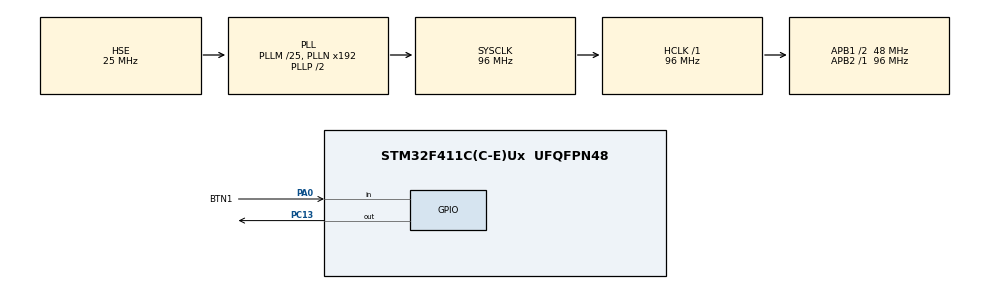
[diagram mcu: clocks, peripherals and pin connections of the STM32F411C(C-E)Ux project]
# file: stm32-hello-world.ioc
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FREERTOS.Queues01=buttonQueue,10,uint8_t,0,Dynamic,NULL,NULL
FREERTOS.Tasks01=defaultTask,24,128,StartDefaultTask,Default,NULL,Dynamic,NULL,NULL;buttonTask,40,128,StartButtonTask,Default,NULL,Dynamic,NULL,NULL
Mcu.Family=STM32F4
Mcu.Name=STM32F411C(C-E)Ux
Mcu.Package=UFQFPN48
NVIC.PriorityGroup=NVIC_PRIORITYGROUP_4
NVIC.TIM1_UP_TIM10_IRQn=true\:15\:0\:false\:false\:true\:false\:false\:true\:true
NVIC.TimeBase=TIM1_UP_TIM10_IRQn
NVIC.TimeBaseIP=TIM1
PA0-WKUP.GPIO_Label=BTN1
PA0-WKUP.GPIO_PuPd=GPIO_PULLUP
PA0-WKUP.Signal=GPIO_Input
PC13-ANTI_TAMP.PinState=GPIO_PIN_RESET
PC13-ANTI_TAMP.Signal=GPIO_Output
PH0\ -\ OSC_IN.Mode=HSE-External-Oscillator
PH0\ -\ OSC_IN.Signal=RCC_OSC_IN
PH1\ -\ OSC_OUT.Mode=HSE-External-Oscillator
PH1\ -\ OSC_OUT.Signal=RCC_OSC_OUT
ProjectManager.HeapSize=0x200
ProjectManager.StackSize=0x400
ProjectManager.TargetToolchain=STM32CubeIDE
RCC.48MHZClocksFreq_Value=48000000
RCC.AHBFreq_Value=96000000
RCC.APB1CLKDivider=RCC_HCLK_DIV2
RCC.APB1Freq_Value=48000000
RCC.APB1TimFreq_Value=96000000
RCC.APB2Freq_Value=96000000
RCC.APB2TimFreq_Value=96000000
RCC.CortexFreq_Value=96000000
RCC.HCLKFreq_Value=96000000
RCC.HSE_VALUE=25000000
RCC.HSI_VALUE=16000000
RCC.LSE_VALUE=32768
RCC.PLLM=25
RCC.PLLSourceVirtual=RCC_PLLSOURCE_HSE
RCC.SYSCLKFreq_VALUE=96000000
RCC.SYSCLKSource=RCC_SYSCLKSOURCE_PLLCLK
RCC.VCOOutputFreq_Value=192000000
VP_FREERTOS_VS_CMSIS_V2.Mode=CMSIS_V2
VP_SYS_VS_tim1.Mode=TIM1
board=custom

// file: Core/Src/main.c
/* USER CODE BEGIN Header */
/**
  ******************************************************************************
  * @file           : main.c
  * @brief          : Main program body
  ******************************************************************************
  * @attention
  *
  * Copyright (c) 2026 STMicroelectronics.
  * All rights reserved.
  *
  * This software is licensed under terms that can be found in the LICENSE file
  * in the root directory of this software component.
  * If no LICENSE file comes with this software, it is provided AS-IS.
  *
  ******************************************************************************
  */
/* USER CODE END Header */
#include "main.h"
#include "cmsis_os.h"

/* Definitions for defaultTask */
osThreadId_t defaultTaskHandle;
const osThreadAttr_t defaultTask_attributes = {
  .name = "defaultTask",
  .stack_size = 128 * 4,
  .priority = (osPriority_t) osPriorityNormal,
};
/* Definitions for buttonTask */
osThreadId_t buttonTaskHandle;
const osThreadAttr_t buttonTask_attributes = {
  .name = "buttonTask",
  .stack_size = 128 * 4,
  .priority = (osPriority_t) osPriorityHigh,
};
/* Definitions for buttonQueue */
osMessageQueueId_t buttonQueueHandle;
const osMessageQueueAttr_t buttonQueue_attributes = {
  .name = "buttonQueue"
};

void SystemClock_Config(void);
static void MX_GPIO_Init(void);
void StartDefaultTask(void *argument);
void StartButtonTask(void *argument);

int main(void)
{

  /* USER CODE BEGIN 1 */
	//TEST 0

  /* USER CODE END 1 */

  /* MCU Configuration--------------------------------------------------------*/

  /* Reset of all peripherals, Initializes the Flash interface and the Systick. */
  HAL_Init();

  /* Configure the system clock */
  SystemClock_Config();

  /* Initialize all configured peripherals */
  MX_GPIO_Init();

  /* Init scheduler */
  osKernelInitialize();

  /* Create the queue(s) */
  /* creation of buttonQueue */
  buttonQueueHandle = osMessageQueueNew (10, sizeof(uint8_t), &buttonQueue_attributes);

  /* Create the thread(s) */
  /* creation of defaultTask */
  defaultTaskHandle = osThreadNew(StartDefaultTask, NULL, &defaultTask_attributes);

  /* creation of buttonTask */
  buttonTaskHandle = osThreadNew(StartButtonTask, NULL, &buttonTask_attributes);

  /* Start scheduler */
  osKernelStart();

  /* We should never get here as control is now taken by the scheduler */

  /* Infinite loop */
  while (1)
  {

  }
}

void SystemClock_Config(void)
{
  RCC_OscInitTypeDef RCC_OscInitStruct = {0};
  RCC_ClkInitTypeDef RCC_ClkInitStruct = {0};

  /** Configure the main internal regulator output voltage
  */
  __HAL_RCC_PWR_CLK_ENABLE();
  __HAL_PWR_VOLTAGESCALING_CONFIG(PWR_REGULATOR_VOLTAGE_SCALE1);

  /** Initializes the RCC Oscillators according to the specified parameters
  * in the RCC_OscInitTypeDef structure.
  */
  RCC_OscInitStruct.OscillatorType = RCC_OSCILLATORTYPE_HSE;
  RCC_OscInitStruct.HSEState = RCC_HSE_ON;
  RCC_OscInitStruct.PLL.PLLState = RCC_PLL_ON;
  RCC_OscInitStruct.PLL.PLLSource = RCC_PLLSOURCE_HSE;
  RCC_OscInitStruct.PLL.PLLM = 25;
  RCC_OscInitStruct.PLL.PLLN = 192;
  RCC_OscInitStruct.PLL.PLLP = RCC_PLLP_DIV2;
  RCC_OscInitStruct.PLL.PLLQ = 4;
  if (HAL_RCC_OscConfig(&RCC_OscInitStruct) != HAL_OK)
  {
    Error_Handler();
  }

  /** Initializes the CPU, AHB and APB buses clocks
  */
  RCC_ClkInitStruct.ClockType = RCC_CLOCKTYPE_HCLK|RCC_CLOCKTYPE_SYSCLK
                              |RCC_CLOCKTYPE_PCLK1|RCC_CLOCKTYPE_PCLK2;
  RCC_ClkInitStruct.SYSCLKSource = RCC_SYSCLKSOURCE_PLLCLK;
  RCC_ClkInitStruct.AHBCLKDivider = RCC_SYSCLK_DIV1;
  RCC_ClkInitStruct.APB1CLKDivider = RCC_HCLK_DIV2;
  RCC_ClkInitStruct.APB2CLKDivider = RCC_HCLK_DIV1;

  if (HAL_RCC_ClockConfig(&RCC_ClkInitStruct, FLASH_LATENCY_3) != HAL_OK)
  {
    Error_Handler();
  }
}

static void MX_GPIO_Init(void)
{
  GPIO_InitTypeDef GPIO_InitStruct = {0};

  /* GPIO Ports Clock Enable */
  __HAL_RCC_GPIOC_CLK_ENABLE();
  __HAL_RCC_GPIOH_CLK_ENABLE();
  __HAL_RCC_GPIOA_CLK_ENABLE();

  /*Configure GPIO pin Output Level */
  HAL_GPIO_WritePin(GPIOC, GPIO_PIN_13, GPIO_PIN_RESET);

  /*Configure GPIO pin : PC13 */
  GPIO_InitStruct.Pin = GPIO_PIN_13;
  GPIO_InitStruct.Mode = GPIO_MODE_OUTPUT_PP;
  GPIO_InitStruct.Pull = GPIO_NOPULL;
  GPIO_InitStruct.Speed = GPIO_SPEED_FREQ_LOW;
  HAL_GPIO_Init(GPIOC, &GPIO_InitStruct);

  /*Configure GPIO pin : BTN1_Pin */
  GPIO_InitStruct.Pin = BTN1_Pin;
  GPIO_InitStruct.Mode = GPIO_MODE_INPUT;
  GPIO_InitStruct.Pull = GPIO_PULLUP;
  HAL_GPIO_Init(BTN1_GPIO_Port, &GPIO_InitStruct);

}

void StartDefaultTask(void *argument)
{
  static uint8_t buttonHeld = 0;

  for(;;)
  {
    uint8_t received;
    if (osMessageQueueGet(buttonQueueHandle, &received, NULL, 0) == osOK)
    {
      buttonHeld = received;
    }

    if (buttonHeld)
      HAL_GPIO_WritePin(GPIOC, GPIO_PIN_13, GPIO_PIN_RESET);
    else
      HAL_GPIO_TogglePin(GPIOC, GPIO_PIN_13);

    osDelay(500);
  }
}
void StartButtonTask(void *argument)
{
  for(;;)
  {
    uint8_t state = (HAL_GPIO_ReadPin(GPIOA, GPIO_PIN_0) == GPIO_PIN_RESET) ? 1 : 0;
    osMessageQueuePut(buttonQueueHandle, &state, 0, 0);
    osDelay(10);
  }
}

void HAL_TIM_PeriodElapsedCallback(TIM_HandleTypeDef *htim)
{
  if (htim->Instance == TIM1)
  {
    HAL_IncTick();
  }
}

void Error_Handler(void)
{
  __disable_irq();
  while (1)
  {
  }
}
